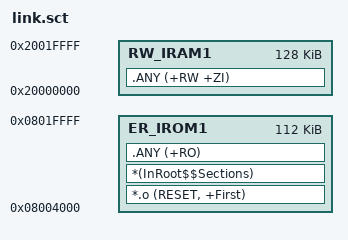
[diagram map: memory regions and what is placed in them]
; *************************************************************
; *** Scatter-Loading Description File generated by uVision ***
; *************************************************************

LR_IROM1 0x08004000 (112 * 1024) {    ;don't change this file,this value define in ubt_common.h.by preprocessor.py change
  ER_IROM1 0x08004000 (112 * 1024)  {  ;don't change this file,this value define in ubt_common.h.by preprocessor.py change
   *.o (RESET, +First)
   *(InRoot$$Sections)
   .ANY (+RO)
  }
  RW_IRAM1 0x20000000 0x00020000  {  ; RW data
   .ANY (+RW +ZI)
  }
}

